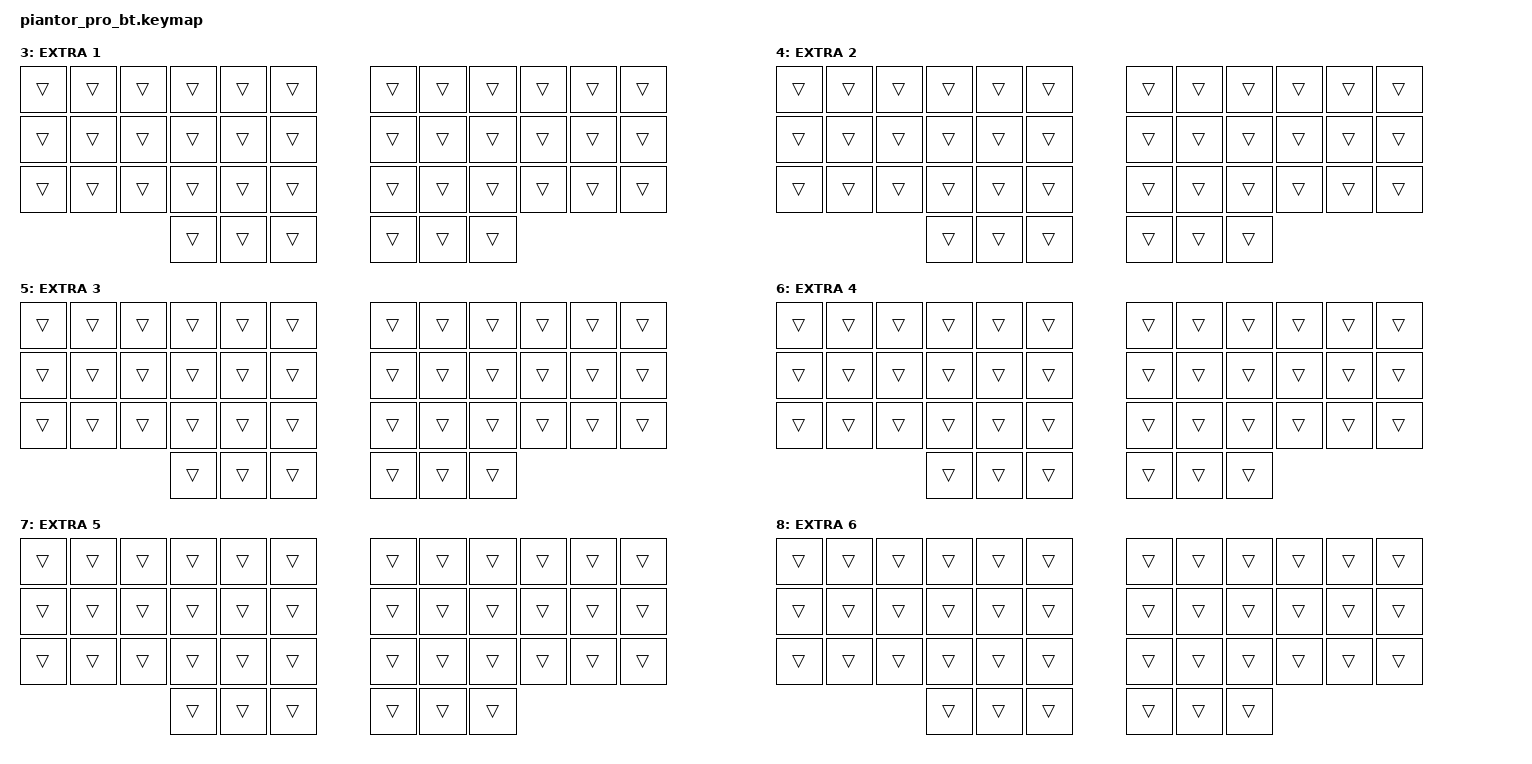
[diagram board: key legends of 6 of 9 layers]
/*
 * Copyright (c) 2020 The ZMK Contributors
 *
 * SPDX-License-Identifier: MIT
 */

#include <behaviors.dtsi>
#include <dt-bindings/zmk/keys.h>
#include <dt-bindings/zmk/bt.h>
#include <dt-bindings/zmk/rgb.h>

// Positional key groups for the 36-key Piantor (5-col layout)
//   0  1  2  3  4    5  6  7  8  9
//  10 11 12 13 14   15 16 17 18 19
//  20 21 22 23 24   25 26 27 28 29
//        30 31 32   33 34 35
#define KEYS_L 0 1 2 3 4 10 11 12 13 14 20 21 22 23 24
#define KEYS_R 5 6 7 8 9 15 16 17 18 19 25 26 27 28 29
#define THUMBS 30 31 32 33 34 35

/ {
    chosen {
        zmk,physical-layout = &five_col_layout;
    };
};

&lt {
    flavor = "balanced";
    tapping-term-ms = <200>;
    quick-tap-ms = <150>;
};

/ {
    behaviors {
        hml: home_row_mod_left {
            compatible = "zmk,behavior-hold-tap";
            #binding-cells = <2>;
            flavor = "balanced";
            tapping-term-ms = <280>;
            quick-tap-ms = <175>;
            require-prior-idle-ms = <150>;
            hold-trigger-key-positions = <KEYS_R THUMBS>;
            hold-trigger-on-release;
            bindings = <&kp>, <&kp>;
        };

        hmr: home_row_mod_right {
            compatible = "zmk,behavior-hold-tap";
            #binding-cells = <2>;
            flavor = "balanced";
            tapping-term-ms = <280>;
            quick-tap-ms = <175>;
            require-prior-idle-ms = <150>;
            hold-trigger-key-positions = <KEYS_L THUMBS>;
            hold-trigger-on-release;
            bindings = <&kp>, <&kp>;
        };
    };
};

/ {
    keymap {
        compatible = "zmk,keymap";

        default_layer {
            display-name = "Gallium";
            // -------------------------------   -------------------------------
            // |  B  |  L  |  D  |  C  |  V  |   |  J  |  Y  |  O  |  U  |  ,  |
            // |  N  |  R  |  T  |  S  |  G  |   |  P  |  H  |  A  |  E  |  I  |
            // |  X  |  Q  |  M  |  W  |  Z  |   |  K  |  F  |  '  |  ;  |  .  |
            //           | ESC | SPACE | TAB |   | ENTER | BACKSPACE | DEL |
            bindings = <
                &kp B       &kp L       &kp D        &kp C         &kp V &kp J &kp Y         &kp O        &kp U       &kp COMMA
                &hml LGUI N &hml LALT R &hml LCTRL T &hml LSHIFT S &kp G &kp P &hmr RSHIFT H &hmr RCTRL A &hmr RALT E &hmr RGUI I
                &kp X       &kp Q       &kp M        &kp W         &kp Z &kp K &kp F         &kp SQT      &kp SEMI    &kp DOT
                                    &lt 1 ESC &kp SPACE &kp TAB &lt 1 RETURN &kp BACKSPACE &kp DELETE
            >;
        };

        lower_layer {
            display-name = "NUMBER";
            // ---------------------------------   -------------------------------
            // |  1  |  2  |  3  |  4  |  5    |   |  6  |  7  |  8  |  9  |  0  |
            // | BT1 | BT2 | BT3 | BT4 | BT5   |   | LFT | DWN |  UP | RGT |     |
            // | BTCR| RGB | RST | BOOT| Unlock|   |     |     |     |     |     |
            //             | GUI |     | SPC   |   | ENT |     | ALT |
            bindings = <
                &kp N1       &kp N2          &kp N3       &kp N4       &kp N5         &kp N6   &kp N7   &kp N8 &kp N9    &kp N0
                &bt BT_SEL 0 &bt BT_SEL 1    &bt BT_SEL 2 &bt BT_SEL 3 &bt BT_SEL 4   &kp LEFT &kp DOWN &kp UP &kp RIGHT &trans
                &bt BT_CLR   &rgb_ug RGB_TOG &sys_reset   &bootloader  &studio_unlock &trans   &bootloader   &trans &trans    &trans
                                             &kp LGUI     &trans       &kp SPACE      &kp LGUI &trans   &kp SPACE
            >;
        };

        raise_layer {
            display-name = "SYMBOL";
            // -------------------------------   -------------------------------
            // |  !  |  @  |  #  |  $  |  %  |   |  ^  |  &  |  *  |  (  |  )  |
            // |     |     |     |     |     |   |  -  |  =  |  [  |  ]  |  \  |
            // |     |     |     |     |     |   |  _  |  +  |  {  |  }  | "|" |
            //             | GUI |     | SPC |   | ENT |     | ALT |
            bindings = <
                &kp EXCL &kp AT &kp HASH &kp DLLR &kp PRCNT  &kp CARET &kp AMPS &kp ASTRK &kp LPAR &kp RPAR
                &trans   &trans &trans   &trans   &trans     &kp MINUS &kp EQUAL &kp LBKT &kp RBKT &kp BSLH
                &trans   &trans &trans   &trans   &trans     &kp UNDER &kp PLUS  &kp LBRC &kp RBRC &kp PIPE
                                &kp LGUI &trans   &kp SPACE  &kp RET   &trans    &kp RALT
            >;
        };

        extra_layer_1 {
            display-name = "EXTRA 1";
            bindings = <
                &trans &trans &trans &trans &trans &trans  &trans &trans &trans &trans &trans &trans
                &trans &trans &trans &trans &trans &trans  &trans &trans &trans &trans &trans &trans
                &trans &trans &trans &trans &trans &trans  &trans &trans &trans &trans &trans &trans
                                     &trans &trans &trans  &trans &trans &trans       
            >;
        };

        extra_layer_2 {
            display-name = "EXTRA 2";
            bindings = <
                &trans &trans &trans &trans &trans &trans  &trans &trans &trans &trans &trans &trans
                &trans &trans &trans &trans &trans &trans  &trans &trans &trans &trans &trans &trans
                &trans &trans &trans &trans &trans &trans  &trans &trans &trans &trans &trans &trans
                                     &trans &trans &trans  &trans &trans &trans       
            >;
        };

        extra_layer_3 {
            display-name = "EXTRA 3";
            bindings = <
                &trans &trans &trans &trans &trans &trans  &trans &trans &trans &trans &trans &trans
                &trans &trans &trans &trans &trans &trans  &trans &trans &trans &trans &trans &trans
                &trans &trans &trans &trans &trans &trans  &trans &trans &trans &trans &trans &trans
                                     &trans &trans &trans  &trans &trans &trans       
            >;
        };

        extra_layer_4 {
            display-name = "EXTRA 4";
            bindings = <
                &trans &trans &trans &trans &trans &trans  &trans &trans &trans &trans &trans &trans
                &trans &trans &trans &trans &trans &trans  &trans &trans &trans &trans &trans &trans
                &trans &trans &trans &trans &trans &trans  &trans &trans &trans &trans &trans &trans
                                     &trans &trans &trans  &trans &trans &trans       
            >;
        };

        extra_layer_5 {
            display-name = "EXTRA 5";
            bindings = <
                &trans &trans &trans &trans &trans &trans  &trans &trans &trans &trans &trans &trans
                &trans &trans &trans &trans &trans &trans  &trans &trans &trans &trans &trans &trans
                &trans &trans &trans &trans &trans &trans  &trans &trans &trans &trans &trans &trans
                                     &trans &trans &trans  &trans &trans &trans       
            >;
        };

        extra_layer_6 {
            display-name = "EXTRA 6";
            bindings = <
                &trans &trans &trans &trans &trans &trans  &trans &trans &trans &trans &trans &trans
                &trans &trans &trans &trans &trans &trans  &trans &trans &trans &trans &trans &trans
                &trans &trans &trans &trans &trans &trans  &trans &trans &trans &trans &trans &trans
                                     &trans &trans &trans  &trans &trans &trans       
            >;
        };
    };
};
